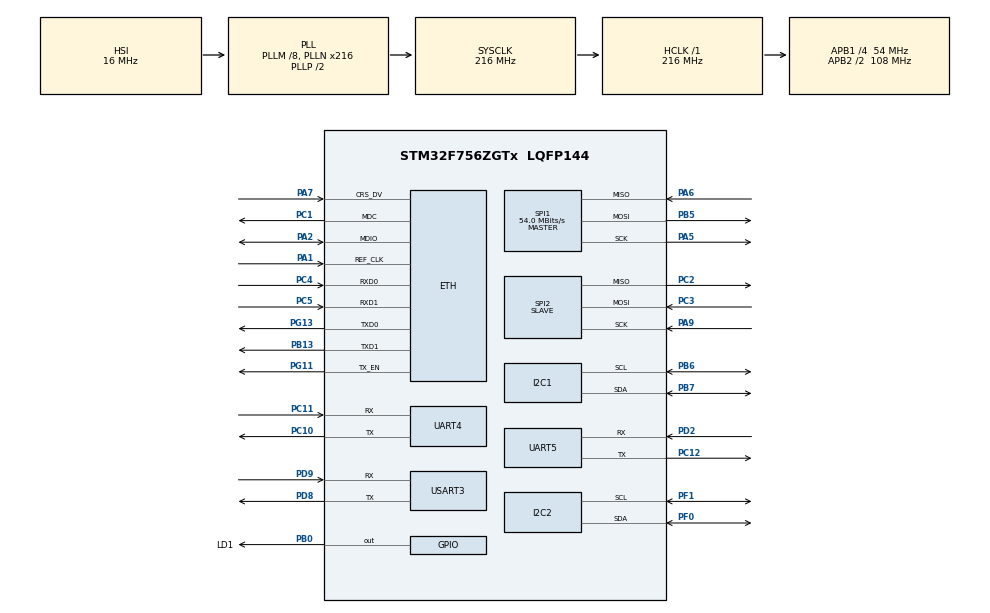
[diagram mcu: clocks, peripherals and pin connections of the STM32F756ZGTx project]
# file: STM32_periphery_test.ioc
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ETH.MediaInterface=HAL_ETH_RMII_MODE
FREERTOS.Tasks01=defaultTask,0,256,StartDefaultTask,Default,NULL,Dynamic,NULL,NULL
FREERTOS.configUSE_NEWLIB_REENTRANT=1
I2C1.Timing=0x20404768
I2C2.Timing=0x20404768
LWIP.BSP.number=1
LWIP.GATEWAY_ADDRESS=010.000.001.100
LWIP.IP_ADDRESS=010.000.001.101
LWIP.LWIP_DHCP=0
LWIP.NETMASK_ADDRESS=225.225.225.000
LWIP.Version=v2.1.2_Cube
LWIP0.BSP.STBoard=false
LWIP0.BSP.api=BSP_COMPONENT_DRIVER
LWIP0.BSP.component=LAN8742
LWIP0.BSP.instance=LAN8742
LWIP0.BSP.name=Driver_PHY
LWIP0.BSP.semaphore=S_LAN8742
LWIP0.BSP.solution=LAN8742
Mcu.Family=STM32F7
Mcu.Name=STM32F756ZGTx
Mcu.Package=LQFP144
NVIC.ETH_IRQn=true\:5\:0\:false\:false\:true\:true\:false\:true\:true
NVIC.I2C1_EV_IRQn=true\:5\:0\:false\:false\:true\:true\:true\:true\:true
NVIC.I2C2_EV_IRQn=true\:5\:0\:false\:false\:true\:true\:true\:true\:true
NVIC.PriorityGroup=NVIC_PRIORITYGROUP_4
NVIC.SPI1_IRQn=true\:5\:0\:false\:false\:true\:true\:true\:true\:true
NVIC.SPI2_IRQn=true\:5\:0\:false\:false\:true\:true\:true\:true\:true
NVIC.TIM6_DAC_IRQn=true\:15\:0\:false\:false\:true\:false\:false\:true\:true
NVIC.TimeBase=TIM6_DAC_IRQn
NVIC.TimeBaseIP=TIM6
NVIC.UART4_IRQn=true\:5\:0\:false\:false\:true\:true\:true\:true\:true
NVIC.UART5_IRQn=true\:5\:0\:false\:false\:true\:true\:true\:true\:true
NVIC.USART3_IRQn=true\:5\:0\:false\:false\:true\:true\:true\:true\:true
PA1.Mode=RMII
PA1.Signal=ETH_REF_CLK
PA13.Mode=Serial_Wire
PA13.Signal=SYS_JTMS-SWDIO
PA14.Mode=Serial_Wire
PA14.Signal=SYS_JTCK-SWCLK
PA2.Mode=RMII
PA2.Signal=ETH_MDIO
PA5.Mode=Full_Duplex_Master
PA5.Signal=SPI1_SCK
PA6.Mode=Full_Duplex_Master
PA6.Signal=SPI1_MISO
PA7.Mode=RMII
PA7.Signal=ETH_CRS_DV
PA9.Mode=Full_Duplex_Slave
PA9.Signal=SPI2_SCK
PB0.GPIO_Label=LD1
PB0.Signal=GPIO_Output
PB13.Mode=RMII
PB13.Signal=ETH_TXD1
PB5.Mode=Full_Duplex_Master
PB5.Signal=SPI1_MOSI
PB6.Mode=I2C
PB6.Signal=I2C1_SCL
PB7.Mode=I2C
PB7.Signal=I2C1_SDA
PC1.Mode=RMII
PC1.Signal=ETH_MDC
PC10.Mode=Asynchronous
PC10.Signal=UART4_TX
PC11.Mode=Asynchronous
PC11.Signal=UART4_RX
PC12.Mode=Asynchronous
PC12.Signal=UART5_TX
PC2.Mode=Full_Duplex_Slave
PC2.Signal=SPI2_MISO
PC3.Mode=Full_Duplex_Slave
PC3.Signal=SPI2_MOSI
PC4.Mode=RMII
PC4.Signal=ETH_RXD0
PC5.Mode=RMII
PC5.Signal=ETH_RXD1
PD2.Mode=Asynchronous
PD2.Signal=UART5_RX
PD8.Mode=Asynchronous
PD8.Signal=USART3_TX
PD9.Mode=Asynchronous
PD9.Signal=USART3_RX
PF0.Mode=I2C
PF0.Signal=I2C2_SDA
PF1.Mode=I2C
PF1.Signal=I2C2_SCL
PG11.Mode=RMII
PG11.Signal=ETH_TX_EN
PG13.Mode=RMII
PG13.Signal=ETH_TXD0
ProjectManager.HeapSize=0x200
ProjectManager.StackSize=0x400
ProjectManager.TargetToolchain=STM32CubeIDE
RCC.48MHZClocksFreq_Value=24000000
RCC.AHBFreq_Value=216000000
RCC.APB1CLKDivider=RCC_HCLK_DIV4
RCC.APB1Freq_Value=54000000
RCC.APB1TimFreq_Value=108000000
RCC.APB2CLKDivider=RCC_HCLK_DIV2
RCC.APB2Freq_Value=108000000
RCC.APB2TimFreq_Value=216000000
RCC.CortexFreq_Value=216000000
RCC.HCLKFreq_Value=216000000
RCC.HSE_VALUE=8000000
RCC.HSI_VALUE=16000000
RCC.LSE_VALUE=32768
RCC.PLLM=8
RCC.PLLMUL=RCC_PLL_MUL9
RCC.PLLN=216
RCC.PRESCALERUSB=RCC_USBCLKSOURCE_PLL_DIV1_5
RCC.SYSCLKFreq_VALUE=216000000
RCC.SYSCLKSource=RCC_SYSCLKSOURCE_PLLCLK
RCC.SYSCLKSourceVirtual=RCC_SYSCLKSOURCE_PLLCLK
RCC.USBFreq_Value=216000000
RCC.VCOOutputFreq_Value=432000000
SPI1.CalculateBaudRate=54.0 MBits/s
SPI1.Direction=SPI_DIRECTION_2LINES
SPI1.Mode=SPI_MODE_MASTER
SPI1.VirtualType=VM_MASTER
SPI2.Direction=SPI_DIRECTION_2LINES
SPI2.Mode=SPI_MODE_SLAVE
SPI2.VirtualType=VM_SLAVE
USART3.VirtualMode-Asynchronous=VM_ASYNC
VP_FREERTOS_VS_CMSIS_V1.Mode=CMSIS_V1
VP_LWIP_VS_Enabled.Mode=Enabled
VP_SYS_VS_tim6.Mode=TIM6
board=NUCLEO-F756ZG

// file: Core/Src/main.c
/* USER CODE BEGIN Header */
/**
  ******************************************************************************
  * @file           : main.c
  * @brief          : Main program body
  ******************************************************************************
  * @attention
  *
  * Copyright (c) 2026 STMicroelectronics.
  * All rights reserved.
  *
  * This software is licensed under terms that can be found in the LICENSE file
  * in the root directory of this software component.
  * If no LICENSE file comes with this software, it is provided AS-IS.
  *
  ******************************************************************************
  */
/* USER CODE END Header */
#include "main.h"
#include "cmsis_os.h"
#include "i2c.h"
#include "lwip.h"
#include "spi.h"
#include "usart.h"
#include "gpio.h"

void SystemClock_Config(void);
void MX_FREERTOS_Init(void);

int main(void)
{

  /* MCU Configuration--------------------------------------------------------*/

  /* Reset of all peripherals, Initializes the Flash interface and the Systick. */
  HAL_Init();

  /* Configure the system clock */
  SystemClock_Config();

  /* Initialize all configured peripherals */
  MX_GPIO_Init();
  MX_I2C1_Init();
  MX_I2C2_Init();
  MX_SPI1_Init();
  MX_SPI2_Init();
  MX_UART4_Init();
  MX_UART5_Init();
  MX_USART3_UART_Init();

  /* Call init function for freertos objects (in cmsis_os2.c) */
  MX_FREERTOS_Init();

  /* Start scheduler */
  osKernelStart();

  /* We should never get here as control is now taken by the scheduler */

  /* Infinite loop */
  while (1)
  {

  }
}

void SystemClock_Config(void)
{
  RCC_OscInitTypeDef RCC_OscInitStruct = {0};
  RCC_ClkInitTypeDef RCC_ClkInitStruct = {0};

  /** Configure the main internal regulator output voltage
  */
  __HAL_RCC_PWR_CLK_ENABLE();
  __HAL_PWR_VOLTAGESCALING_CONFIG(PWR_REGULATOR_VOLTAGE_SCALE1);

  /** Initializes the RCC Oscillators according to the specified parameters
  * in the RCC_OscInitTypeDef structure.
  */
  RCC_OscInitStruct.OscillatorType = RCC_OSCILLATORTYPE_HSI;
  RCC_OscInitStruct.HSIState = RCC_HSI_ON;
  RCC_OscInitStruct.HSICalibrationValue = RCC_HSICALIBRATION_DEFAULT;
  RCC_OscInitStruct.PLL.PLLState = RCC_PLL_ON;
  RCC_OscInitStruct.PLL.PLLSource = RCC_PLLSOURCE_HSI;
  RCC_OscInitStruct.PLL.PLLM = 8;
  RCC_OscInitStruct.PLL.PLLN = 216;
  RCC_OscInitStruct.PLL.PLLP = RCC_PLLP_DIV2;
  RCC_OscInitStruct.PLL.PLLQ = 2;
  if (HAL_RCC_OscConfig(&RCC_OscInitStruct) != HAL_OK)
  {
    Error_Handler();
  }

  /** Activate the Over-Drive mode
  */
  if (HAL_PWREx_EnableOverDrive() != HAL_OK)
  {
    Error_Handler();
  }

  /** Initializes the CPU, AHB and APB buses clocks
  */
  RCC_ClkInitStruct.ClockType = RCC_CLOCKTYPE_HCLK|RCC_CLOCKTYPE_SYSCLK
                              |RCC_CLOCKTYPE_PCLK1|RCC_CLOCKTYPE_PCLK2;
  RCC_ClkInitStruct.SYSCLKSource = RCC_SYSCLKSOURCE_PLLCLK;
  RCC_ClkInitStruct.AHBCLKDivider = RCC_SYSCLK_DIV1;
  RCC_ClkInitStruct.APB1CLKDivider = RCC_HCLK_DIV4;
  RCC_ClkInitStruct.APB2CLKDivider = RCC_HCLK_DIV2;

  if (HAL_RCC_ClockConfig(&RCC_ClkInitStruct, FLASH_LATENCY_7) != HAL_OK)
  {
    Error_Handler();
  }
}

void HAL_TIM_PeriodElapsedCallback(TIM_HandleTypeDef *htim)
{
  if (htim->Instance == TIM6)
  {
    HAL_IncTick();
  }
}

void Error_Handler(void)
{
  __disable_irq();
  while (1)
  {
  }
}

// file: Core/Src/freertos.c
/* USER CODE BEGIN Header */
/**
  ******************************************************************************
  * File Name          : freertos.c
  * Description        : Code for freertos applications
  ******************************************************************************
  * @attention
  *
  * Copyright (c) 2026 STMicroelectronics.
  * All rights reserved.
  *
  * This software is licensed under terms that can be found in the LICENSE file
  * in the root directory of this software component.
  * If no LICENSE file comes with this software, it is provided AS-IS.
  *
  ******************************************************************************
  */
/* USER CODE END Header */

#include "FreeRTOS.h"
#include "task.h"
#include "main.h"
#include "cmsis_os.h"

/* USER CODE BEGIN Includes */
#include "rtg.h"
#include "usart.h"
/* USER CODE END Includes */

osThreadId defaultTaskHandle;

void StartDefaultTask(void const * argument);

extern void MX_LWIP_Init(void);
void MX_FREERTOS_Init(void); /* (MISRA C 2004 rule 8.1) */

/* GetIdleTaskMemory prototype (linked to static allocation support) */
void vApplicationGetIdleTaskMemory( StaticTask_t **ppxIdleTaskTCBBuffer, StackType_t **ppxIdleTaskStackBuffer, uint32_t *pulIdleTaskStackSize );

/* USER CODE BEGIN GET_IDLE_TASK_MEMORY */
static StaticTask_t xIdleTaskTCBBuffer;
static StackType_t xIdleStack[configMINIMAL_STACK_SIZE];

void vApplicationGetIdleTaskMemory( StaticTask_t **ppxIdleTaskTCBBuffer, StackType_t **ppxIdleTaskStackBuffer, uint32_t *pulIdleTaskStackSize )
{
  *ppxIdleTaskTCBBuffer = &xIdleTaskTCBBuffer;
  *ppxIdleTaskStackBuffer = &xIdleStack[0];
  *pulIdleTaskStackSize = configMINIMAL_STACK_SIZE;
  /* place for user code */
}
/* USER CODE END GET_IDLE_TASK_MEMORY */

void MX_FREERTOS_Init(void) {
  /* USER CODE BEGIN Init */
	rtg_init();
  /* USER CODE END Init */

  /* Create the thread(s) */
  /* definition and creation of defaultTask */
  osThreadDef(defaultTask, StartDefaultTask, osPriorityNormal, 0, 256);
  defaultTaskHandle = osThreadCreate(osThread(defaultTask), NULL);

}

void StartDefaultTask(void const * argument)
{
  /* init code for LWIP */
  MX_LWIP_Init();
  for(;;)
  {
    osDelay(1);
  }
}
